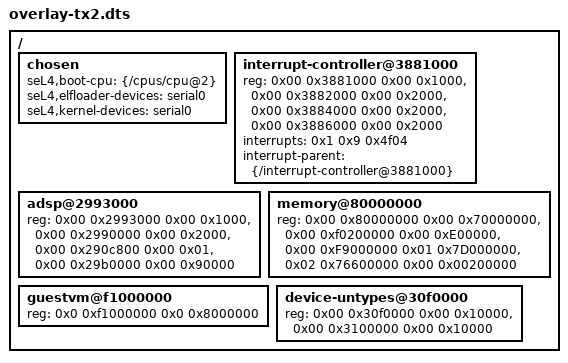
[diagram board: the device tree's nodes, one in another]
/*
 * Copyright 2020, Data61, CSIRO (ABN 41 687 119 230)
 *
 * SPDX-License-Identifier: GPL-2.0-only
 */

/ {
	/* seL4 on the TX2 boots on the first non-NVIDIA core */
	chosen {
		seL4,boot-cpu = <&{/cpus/cpu@2}>;
		seL4,elfloader-devices =
		    "serial0",
		    &{/psci};
		seL4,kernel-devices =
		    "serial0",
		    &{/interrupt-controller@3881000},
		    &{/iommu@12000000},
		    &{/timer};
	};


	/* Virtualisation stuff for the GIC */
	interrupt-controller@3881000 {
		reg = <0x00 0x3881000 0x00 0x1000>,
			<0x00 0x3882000 0x00 0x2000>,
			<0x00 0x3884000 0x00 0x2000>,
			<0x00 0x3886000 0x00 0x2000>;
		interrupts = <0x1 0x9 0x4f04>;
		interrupt-parent = <&{/interrupt-controller@3881000}>;
	};

	adsp@2993000 {
		/* Remove memory regions which expose RAM or are otherwise garbage */
		reg = <0x00 0x2993000 0x00 0x1000>,
				<0x00 0x2990000 0x00 0x2000>,
				/*<0x00 0x00 0x00 0x01>,*/
				<0x00 0x290c800 0x00 0x01>,
				<0x00 0x29b0000 0x00 0x90000>;
				/*<0x00 0x40000000 0x00 0xc0000000>,*/
				/*<0x00 0x00 0x00 0x01>;*/
	};

	memory@80000000 {
		/*
		 * These values are passed to U-Boot by earlier boot stages, and
		 * aren't included in the DTS.
		 */
		reg = <0x00 0x80000000 0x00 0x70000000>,
				<0x00 0xf0200000 0x00 0xE00000>,
                <0x00 0xF9000000 0x01 0x7D000000>,
				<0x02 0x76600000 0x00 0x00200000>;
	};

    guestvm@f1000000 {
        reg = <0x0 0xf1000000 0x0 0x8000000>;
        status = "okay";
    };

    device-untypes@30f0000 {
        /*
         * These are missing device untypeds.
         */
        reg = <0x00 0x30f0000 0x00 0x10000>,
              <0x00 0x3100000 0x00 0x10000>;
    };
};

